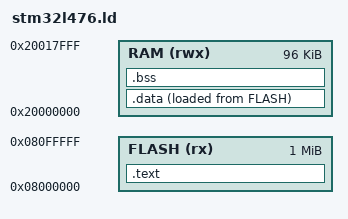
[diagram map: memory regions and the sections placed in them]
/* STM32L476 Linker Script for LabWired Builder */
ENTRY(Reset_Handler)

MEMORY
{
  FLASH (rx) : ORIGIN = 0x08000000, LENGTH = 1024K
  RAM  (rwx) : ORIGIN = 0x20000000, LENGTH = 96K
}

SECTIONS
{
    .text :
    {
        KEEP(*(.vectors))
        *(.text*)
        *(.rodata*)
    } > FLASH

    .data :
    {
        _sdata = .;
        *(.data*)
        _edata = .;
    } > RAM AT > FLASH

    _sidata = LOADADDR(.data);

    .bss :
    {
        _sbss = .;
        *(.bss*)
        *(COMMON)
        _ebss = .;
    } > RAM

    _estack = ORIGIN(RAM) + LENGTH(RAM);
}
